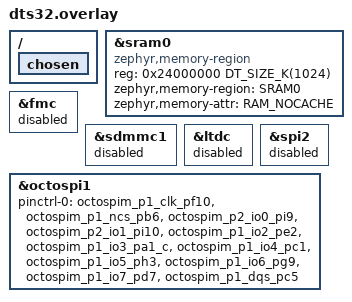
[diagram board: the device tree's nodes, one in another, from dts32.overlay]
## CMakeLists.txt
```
#
# Copyright (c) 2022 Nordic Semiconductor ASA
#
# SPDX-License-Identifier: LicenseRef-Nordic-5-Clause
#

cmake_minimum_required(VERSION 3.20.0)

find_package(Zephyr REQUIRED HINTS $ENV{ZEPHYR_BASE})
project(nrf_wifi_shell)

target_sources(app PRIVATE src/main.c)
```

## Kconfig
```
#
# Copyright (c) 2023 Nordic Semiconductor
#
# SPDX-License-Identifier: LicenseRef-Nordic-5-Clause
#

source "Kconfig.zephyr"

menu "Nordic Scan sample"

config APP_ENABLE_QSPI
	bool "select qspi driver"
	select USE_STM32_HAL_OSPI
	select USE_STM32_HAL_GPIO
	select USE_STM32_HAL_MDMA

endmenu
```

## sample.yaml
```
sample:
  description: Wi-Fi shell sample
    application
  name: Wi-Fi shell
tests:
  sample.nrf7002.shell:
    build_only: true
    integration_platforms:
      - nrf7002dk_nrf5340_cpuapp
    platform_allow: nrf7002dk_nrf5340_cpuapp
    tags: ci_build
  sample.nrf7001.shell:
    build_only: true
    integration_platforms:
      - nrf7002dk_nrf7001_nrf5340_cpuapp
    platform_allow: nrf7002dk_nrf7001_nrf5340_cpuapp
    tags: ci_build
  sample.nrf7002_eks.shell:
    build_only: true
    extra_args: SHIELD=nrf7002ek
    integration_platforms:
      - nrf5340dk_nrf5340_cpuapp
      - nrf52840dk_nrf52840
    platform_allow: nrf5340dk_nrf5340_cpuapp nrf52840dk_nrf52840
    tags: ci_build
  sample.nrf7000_eks.shell:
    build_only: true
    extra_args: SHIELD=nrf7002ek_nrf7000 CONFIG_WPA_SUPP=n
    integration_platforms:
      - nrf5340dk_nrf5340_cpuapp
      - nrf52840dk_nrf52840
    platform_allow: nrf5340dk_nrf5340_cpuapp nrf52840dk_nrf52840
    tags: ci_build
  sample.nrf7001_eks.shell:
    build_only: true
    extra_args: SHIELD=nrf7002ek_nrf7001
    integration_platforms:
      - nrf5340dk_nrf5340_cpuapp
      - nrf52840dk_nrf52840
    platform_allow: nrf5340dk_nrf5340_cpuapp nrf52840dk_nrf52840
    tags: ci_build
  sample.nrf7002_eks_cpunet.shell:
    build_only: true
    extra_args: SHIELD=nrf7002ek CONFIG_BOARD_ENABLE_CPUNET=y
    integration_platforms:
      - nrf5340dk_nrf5340_cpuapp
    platform_allow: nrf5340dk_nrf5340_cpuapp
    tags: ci_build
  sample.nrf7000_eks_cpunet.shell:
    build_only: true
    extra_args: SHIELD=nrf7002ek_nrf7000 CONFIG_BOARD_ENABLE_CPUNET=y CONFIG_WPA_SUPP=n
    integration_platforms:
      - nrf5340dk_nrf5340_cpuapp
    platform_allow: nrf5340dk_nrf5340_cpuapp
    tags: ci_build
  sample.nrf7001_eks_cpunet.shell:
    build_only: true
    extra_args: SHIELD=nrf7002ek_nrf7001 CONFIG_BOARD_ENABLE_CPUNET=y
    integration_platforms:
      - nrf5340dk_nrf5340_cpuapp
    platform_allow: nrf5340dk_nrf5340_cpuapp
    tags: ci_build
  sample.nrf7002.shell.zperf:
    build_only: true
    extra_args: OVERLAY_CONFIG=overlay-zperf.conf
    integration_platforms:
      - nrf7002dk_nrf5340_cpuapp
    platform_allow: nrf7002dk_nrf5340_cpuapp
    tags: ci_build
  sample.nrf7001.shell.zperf:
    build_only: true
    extra_args: OVERLAY_CONFIG=overlay-zperf.conf
    integration_platforms:
      - nrf7002dk_nrf7001_nrf5340_cpuapp
    platform_allow: nrf7002dk_nrf7001_nrf5340_cpuapp
    tags: ci_build
  sample.nrf7002.shell.wpa_cli:
    build_only: true
    extra_args: CONFIG_WPA_CLI=y
    integration_platforms:
      - nrf7002dk_nrf5340_cpuapp
    platform_allow: nrf7002dk_nrf5340_cpuapp
    tags: ci_build
  sample.nrf7001.shell.wpa_cli:
    build_only: true
    extra_args: CONFIG_WPA_CLI=y
    integration_platforms:
      - nrf7002dk_nrf7001_nrf5340_cpuapp
    platform_allow: nrf7002dk_nrf7001_nrf5340_cpuapp
    tags: ci_build
  sample.nrf7002.shell.scan_only_7002:
    build_only: true
    extra_args: OVERLAY_CONFIG=overlay-scan-only.conf
    integration_platforms:
      - nrf7002dk_nrf5340_cpuapp
    platform_allow: nrf7002dk_nrf5340_cpuapp
    tags: ci_build
  sample.nrf7002.shell.scan_only_9160:
    build_only: true
    extra_args: OVERLAY_CONFIG=overlay-scan-only.conf SHIELD=nrf7002ek
    integration_platforms:
      - nrf9160dk_nrf9160_ns
    platform_allow: nrf9160dk_nrf9160_ns
    tags: ci_build
  sample.nrf7000.shell.scan_only_9160:
    build_only: true
    extra_args: OVERLAY_CONFIG=overlay-scan-only.conf SHIELD=nrf7002ek_nrf7000 CONFIG_WPA_SUPP=n
    integration_platforms:
      - nrf9160dk_nrf9160_ns
    platform_allow: nrf9160dk_nrf9160_ns
    tags: ci_build
  sample.nrf7001.shell.scan_only_9160:
    build_only: true
    extra_args: OVERLAY_CONFIG=overlay-scan-only.conf SHIELD=nrf7002ek_nrf7001
    integration_platforms:
      - nrf9160dk_nrf9160_ns
    platform_allow: nrf9160dk_nrf9160_ns
    tags: ci_build
  sample.nrf7002.shell.otbr:
    build_only: true
    extra_args: OVERLAY_CONFIG=overlay-openthread.conf
    integration_platforms:
      - nrf7002dk_nrf5340_cpuapp
    platform_allow: nrf7002dk_nrf5340_cpuapp
    tags: ci_build
  sample.nrf7002.shell.posix_names:
    build_only: true
    extra_args: CONFIG_POSIX_API=n CONIFG_NET_SOCKETS_POSIX_NAMES=y
    integration_platforms:
      - nrf7002dk_nrf5340_cpuapp
    platform_allow: nrf7002dk_nrf5340_cpuapp
    tags: ci_build
  sample.nrf7002_ns.shell:
    build_only: true
    extra_args: OVERLAY_CONFIG=overlay-tfm.conf
    integration_platforms:
      - nrf7002dk_nrf5340_cpuapp_ns
    platform_allow: nrf7002dk_nrf5340_cpuapp_ns
  sample.nrf7002_eb.thingy53.shell:
    build_only: true
    extra_args: SHIELD=nrf7002eb CONFIG_BOARD_ENABLE_CPUNET=y
    integration_platforms:
      - thingy53_nrf5340_cpuapp
    platform_allow: thingy53_nrf5340_cpuapp
    tags: ci_build
  # Used by QA and also acts as a memory stress test
  sample.nrf7001.superset:
    build_only: true
    extra_args:
      OVERLAY_CONFIG=overlay-zperf.conf
      CONFIG_NRF700X_UTIL=y
      CONFIG_WPA_CLI=y
      CONFIG_NET_IPV4_FRAGMENT=y
      CONFIG_NET_IPV4_FRAGMENT_MAX_PKT=24
    integration_platforms:
      - nrf7002dk_nrf7001_nrf5340_cpuapp
    platform_allow: nrf7002dk_nrf7001_nrf5340_cpuapp
    tags: ci_build_superset
  # Used by QA and also acts as a memory stress test
  sample.nrf7001_ek.superset:
    build_only: true
    extra_args:
      SHIELD=nrf7002ek_nrf7001
      OVERLAY_CONFIG=overlay-zperf.conf
      CONFIG_NRF700X_UTIL=y
      CONFIG_WPA_CLI=y
      CONFIG_NET_IPV4_FRAGMENT=y
      CONFIG_NET_IPV4_FRAGMENT_MAX_PKT=24
    integration_platforms:
      - nrf5340dk_nrf5340_cpuapp
    platform_allow: nrf5340dk_nrf5340_cpuapp
    tags: ci_build_superset
  # Used by QA and also acts as a memory stress test
  sample.nrf7002.superset:
    build_only: true
    extra_args:
      OVERLAY_CONFIG=overlay-zperf.conf
      CONFIG_NRF700X_UTIL=y
      CONFIG_WPA_CLI=y
      CONFIG_NET_IPV4_FRAGMENT=y
      CONFIG_NET_IPV4_FRAGMENT_MAX_PKT=24
    integration_platforms:
      - nrf7002dk_nrf5340_cpuapp
    platform_allow: nrf7002dk_nrf5340_cpuapp
    tags: ci_build_superset
  # Used by QA and also acts as a memory stress test
  sample.nrf7002_ek.superset:
    build_only: true
    extra_args:
      SHIELD=nrf7002ek
      OVERLAY_CONFIG=overlay-zperf.conf
      CONFIG_NRF700X_UTIL=y
      CONFIG_WPA_CLI=y
      CONFIG_NET_IPV4_FRAGMENT=y
      CONFIG_NET_IPV4_FRAGMENT_MAX_PKT=24
    integration_platforms:
      - nrf5340dk_nrf5340_cpuapp
    platform_allow: nrf5340dk_nrf5340_cpuapp
    tags: ci_build_superset
  sample.nrf7002.superset.debug:
    build_only: true
    extra_args:
      OVERLAY_CONFIG=overlay-debug.conf;overlay-zperf.conf
      CONFIG_NRF700X_UTIL=y
      CONFIG_WPA_CLI=y
      CONFIG_NET_IPV4_FRAGMENT=y
      CONFIG_NET_IPV4_FRAGMENT_MAX_PKT=24
    integration_platforms:
      - nrf7002dk_nrf5340_cpuapp
    platform_allow: nrf7002dk_nrf5340_cpuapp
    tags: ci_build_superset
```

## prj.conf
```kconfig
#
# Copyright (c) 2022 Nordic Semiconductor ASA
#
# SPDX-License-Identifier: LicenseRef-Nordic-5-Clause
#
CONFIG_WIFI=y
CONFIG_WIFI_NRF700X=y

# WPA supplicant
CONFIG_WPA_SUPP=y
CONFIG_NET_L2_WIFI_SHELL=y

# System settings
CONFIG_NEWLIB_LIBC=y
CONFIG_NEWLIB_LIBC_NANO=n

# Networking
CONFIG_NETWORKING=y
CONFIG_NET_SOCKETS=y
CONFIG_NET_LOG=y
CONFIG_NET_IPV6=y
CONFIG_NET_IPV4=y
CONFIG_NET_UDP=y
CONFIG_NET_TCP=y
CONFIG_NET_DHCPV4=y
CONFIG_DNS_RESOLVER=y

CONFIG_NET_STATISTICS=y
CONFIG_NET_STATISTICS_WIFI=y
CONFIG_NET_STATISTICS_USER_API=y

CONFIG_NET_PKT_RX_COUNT=8
CONFIG_NET_PKT_TX_COUNT=8

# Below section is the primary contributor to SRAM and is currently
# tuned for performance, but this will be revisited in the future.
CONFIG_NET_BUF_RX_COUNT=16
CONFIG_NET_BUF_TX_COUNT=16
CONFIG_NET_BUF_DATA_SIZE=128
CONFIG_NRF700X_RX_NUM_BUFS=16
CONFIG_NRF700X_MAX_TX_AGGREGATION=4
# nRF700x is main consumer: (16 + 8) * 1600 = ~40KB + ~40KB control path (experimental)
CONFIG_HEAP_MEM_POOL_SIZE=80000
CONFIG_NET_TC_TX_COUNT=1

CONFIG_NET_IF_UNICAST_IPV6_ADDR_COUNT=4
CONFIG_NET_IF_MCAST_IPV6_ADDR_COUNT=5
CONFIG_NET_MAX_CONTEXTS=5
CONFIG_NET_CONTEXT_SYNC_RECV=y

CONFIG_INIT_STACKS=y

CONFIG_NET_L2_ETHERNET=y
CONFIG_NET_SHELL=y

# Memories
CONFIG_MAIN_STACK_SIZE=4096
CONFIG_SHELL_STACK_SIZE=4096
CONFIG_NET_TX_STACK_SIZE=4096
CONFIG_NET_RX_STACK_SIZE=4096

# Debugging
CONFIG_STACK_SENTINEL=y
CONFIG_DEBUG_COREDUMP=y
CONFIG_DEBUG_COREDUMP_BACKEND_LOGGING=y
CONFIG_DEBUG_COREDUMP_MEMORY_DUMP_MIN=y
CONFIG_SHELL_CMDS_RESIZE=n
#CONFIG_DEBUG=y
CONFIG_WPA_SUPP_LOG_LEVEL_INF=y

# Kernel options
CONFIG_ENTROPY_GENERATOR=y

# Logging
CONFIG_LOG=y
CONFIG_PRINTK=y
CONFIG_SHELL=y
CONFIG_SHELL_GETOPT=y
CONFIG_DEVICE_SHELL=y
CONFIG_POSIX_CLOCK=y
CONFIG_DATE_SHELL=y
CONFIG_NET_CONFIG_AUTO_INIT=n

CONFIG_WIFI_MGMT_EXT=y
CONFIG_WIFI_CREDENTIALS=y
CONFIG_WIFI_CREDENTIALS_BACKEND_SETTINGS=y
CONFIG_FLASH=y
CONFIG_FLASH_PAGE_LAYOUT=y
CONFIG_FLASH_MAP=y
CONFIG_NVS=y
CONFIG_SETTINGS=y
CONFIG_SETTINGS_NVS=y

# printing of scan results puts pressure on queues in new locking
# design in net_mgmt. So, use a higher timeout for a crowded
# environment.
CONFIG_NET_MGMT_EVENT_QUEUE_TIMEOUT=5000


CONFIG_NRF_WIFI_LOW_POWER=n
CONFIG_APP_ENABLE_QSPI=y
CONFIG_DCACHE=n
CONFIG_WPA_SUPP_CRYPTO_LEGACY_BUILTIN=y
CONFIG_ENTROPY_GENERATOR=y
CONFIG_ENTROPY_STM32_RNG=y
CONFIG_ENTROPY_DEVICE_RANDOM_GENERATOR=y
CONFIG_WIFI_MGMT_EXT=n
CONFIG_WIFI_CREDENTIALS=n
CONFIG_WIFI_CREDENTIALS_BACKEND_SETTINGS=n
CONFIG_FLASH=n
CONFIG_FLASH_PAGE_LAYOUT=n
CONFIG_FLASH_MAP=n
CONFIG_NVS=n
CONFIG_SETTINGS=n
CONFIG_SETTINGS_NVS=n

CONFIG_NET_ZPERF=y
CONFIG_POSIX_MAX_FDS=16
# Optimized networking settings for performance
CONFIG_NET_PKT_RX_COUNT=100
CONFIG_NET_PKT_TX_COUNT=100
CONFIG_NET_BUF_RX_COUNT=100
CONFIG_NET_BUF_TX_COUNT=100
CONFIG_HEAP_MEM_POOL_SIZE=300000
CONFIG_NET_BUF_DATA_SIZE=1600
CONFIG_NRF700X_QSPI_LOW_POWER=n
#CONFIG_SPEED_OPTIMIZATIONS=y

# Necessary for zperf_tcp_receiver.c
CONFIG_NET_CONFIG_SETTINGS=y
CONFIG_NET_CONFIG_INIT_TIMEOUT=0

CONFIG_NRF700X_MAX_TX_AGGREGATION=12
CONFIG_NRF700X_MAX_TX_TOKENS=12
CONFIG_SPEED_OPTIMIZATIONS=y

CONFIG_ZPERF_WORK_Q_THREAD_PRIORITY=5
# CONFIG_NRF700X_BH_WQ_PRIORITY=0
# CONFIG_NRF700X_MAX_TX_PENDING_QLEN=30

CONFIG_NET_ZPERF_MAX_PACKET_SIZE=1500

# add by liming
CONFIG_TEST_RANDOM_GENERATOR=y
CONFIG_ENTROPY_DEVICE_RANDOM_GENERATOR=y
CONFIG_HARDWARE_DEVICE_CS_GENERATOR=y
```

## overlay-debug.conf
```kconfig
CONFIG_SHELL=y
CONFIG_SHELL_STACK_SIZE=4096
CONFIG_NET_SHELL=y
CONFIG_SHELL_GETOPT=y
CONFIG_SHELL_CMDS_RESIZE=n
CONFIG_NRF700X_UTIL=y
CONFIG_NET_L2_WIFI_SHELL=y
CONFIG_NET_STATISTICS=y
CONFIG_NET_STATISTICS_WIFI=y
CONFIG_NET_STATISTICS_USER_API=y
CONFIG_SYS_HEAP_RUNTIME_STATS=y
CONFIG_LOG=y
CONFIG_PRINTK=y
CONFIG_LOG_MODE_IMMEDIATE=y
CONFIG_WPA_SUPP_LOG_LEVEL_DBG=y
```

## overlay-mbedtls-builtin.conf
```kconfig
CONFIG_WPA_SUPP_CRYPTO_LEGACY_BUILTIN=y
CONFIG_MBEDTLS_BUILTIN=y
CONFIG_ENTROPY_GENERATOR=y
# To fix Kconfig MD5 warning
CONFIG_NET_TCP_ISN_RFC6528=n
```

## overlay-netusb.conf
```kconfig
# USB Device settings
CONFIG_USB_DEVICE_STACK=y

# Select USB Configurations
CONFIG_USB_DEVICE_NETWORK_ECM=y

# Logging
CONFIG_USB_DRIVER_LOG_LEVEL_INF=y
CONFIG_USB_DEVICE_LOG_LEVEL_INF=y

# Uses more Selects
CONFIG_NET_SOCKETS_POLL_MAX=10

# DUT responses are > 1500, so, need to fragment
CONFIG_NET_IPV4_FRAGMENT=y
CONFIG_NET_IPV4_FRAGMENT_MAX_COUNT=10

# For netusb WFA_THREADS_NUM
CONFIG_MAX_PTHREAD_COUNT=5
# Every pthread_create needs a mutex, and WFA DUT needs an extra mutex/thread
# CONFIG_MAX_PTHREAD_COUNT * 2
CONFIG_MAX_PTHREAD_MUTEX_COUNT=10
# Same as above: CONFIG_MAX_PTHREAD_COUNT * 2
CONFIG_MAX_PTHREAD_COND_COUNT=10
```

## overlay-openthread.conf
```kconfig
# for wifi_shell to work
CONFIG_NET_DEFAULT_IF_ETHERNET=y
CONFIG_NET_CONFIG_AUTO_INIT=n
CONFIG_NET_CONFIG_SETTINGS=y
CONFIG_NET_CONFIG_INIT_TIMEOUT=0

CONFIG_OPENTHREAD_SHELL=y
CONFIG_SHELL_ARGC_MAX=26
CONFIG_SHELL_CMD_BUFF_SIZE=416

# Enable OpenThread features set
CONFIG_OPENTHREAD_NORDIC_LIBRARY_MASTER=y

CONFIG_NET_L2_OPENTHREAD=y
# Openthread supports only IPv6 and is the first interface
CONFIG_NET_CONFIG_MY_IPV4_ADDR=""
CONFIG_NET_CONFIG_PEER_IPV4_ADDR=""

CONFIG_ASSERT=y
CONFIG_ASSERT_NO_COND_INFO=y
CONFIG_FPU=y

CONFIG_GPIO_SHELL=y

# Use printk to log messages
CONFIG_LOG_MODE_MINIMAL=y

# Log only errors/hard faults
CONFIG_LOG_MAX_LEVEL=1
```

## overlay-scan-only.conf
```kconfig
# Scan only using offload API
CONFIG_WPA_SUPP=n
# In 9160 default is socket interface
CONFIG_NET_DEFAULT_IF_ETHERNET=y
CONFIG_MBEDTLS=n
CONFIG_NORDIC_SECURITY_BACKEND=n
# If MbedTLS is enabled, use the standard files
CONFIG_GENERATE_MBEDTLS_CFG_FILE=y

# Disable unused networking options
CONFIG_NET_SOCKETS=n
CONFIG_POSIX_API=n
CONFIG_NET_LOG=n
CONFIG_NET_IPV6=n
CONFIG_NET_TCP=n
CONFIG_DNS_RESOLVER=n

# Memories
CONFIG_NET_PKT_RX_COUNT=1
CONFIG_NET_PKT_TX_COUNT=1
# Needed to handle more scan results
CONFIG_HEAP_MEM_POOL_SIZE=25000
```

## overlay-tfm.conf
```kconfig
#
# Copyright (c) 2023 Nordic Semiconductor ASA
#
# SPDX-License-Identifier: LicenseRef-Nordic-5-Clause
#
CONFIG_NET_STATISTICS=n
CONFIG_NET_STATISTICS_WIFI=n
CONFIG_NET_STATISTICS_USER_API=n

CONFIG_NET_PKT_RX_COUNT=8
CONFIG_NET_PKT_TX_COUNT=4

# Below section is the primary contributor to SRAM and is currently
# tuned for performance, but this will be revisited in the future.
CONFIG_NET_BUF_RX_COUNT=8
CONFIG_NET_BUF_TX_COUNT=8
CONFIG_NET_BUF_DATA_SIZE=128
CONFIG_HEAP_MEM_POOL_SIZE=153600
CONFIG_NET_TC_TX_COUNT=1

CONFIG_NET_TX_STACK_SIZE=2048
CONFIG_NET_RX_STACK_SIZE=2048

# printing of scan results puts pressure on queues in new locking
# design in net_mgmt. So, use a higher timeout for a crowded
# environment.
CONFIG_NET_MGMT_EVENT_QUEUE_TIMEOUT=5000

CONFIG_MBEDTLS_PSA_CRYPTO_C=y
CONFIG_MBEDTLS_HEAP_SIZE=1024
```

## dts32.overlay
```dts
#include <st/h7/stm32h7b3lihxq-pinctrl.dtsi>

/delete-node/ &sram1;
/delete-node/ &sram2;
&sram0 {
	compatible = "zephyr,memory-region", "mmio-sram";
	reg = < 0x24000000 DT_SIZE_K(1024) >;
	zephyr,memory-region = "SRAM0";
	zephyr,memory-attr = "RAM_NOCACHE";
};

/{
	chosen {
		/delete-property/ zephyr,dtcm;
		/delete-property/ zephyr,itcm;
	};

};

&fmc {
	status = "disabled";
};

&sdmmc1 {
	status = "disabled";
};

&ltdc {
	status = "disabled";
};

&spi2 {
	status = "disabled";
};

&octospi1 {
	pinctrl-0 = <&octospim_p1_clk_pf10 &octospim_p1_ncs_pb6
		     &octospim_p2_io0_pi9 &octospim_p2_io1_pi10
		     &octospim_p1_io2_pe2 &octospim_p1_io3_pa1_c
		     &octospim_p1_io4_pc1 &octospim_p1_io5_ph3
		     &octospim_p1_io6_pg9 &octospim_p1_io7_pd7
		     &octospim_p1_dqs_pc5>;
	pinctrl-names = "default";

	status = "okay";	
};

// &pll {
// 	mul-n = <30>;

// };

// &rcc {
// 	clock-frequency = <DT_FREQ_M(240)>;
// };
```

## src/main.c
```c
/*
 * Copyright (c) 2022 Nordic Semiconductor ASA
 *
 * SPDX-License-Identifier: LicenseRef-Nordic-5-Clause
 */

/** @file
 * @brief WiFi shell sample main function
 */

#include <zephyr/sys/printk.h>
#include <zephyr/kernel.h>
#if defined(CLOCK_FEATURE_HFCLK_DIVIDE_PRESENT) || NRF_CLOCK_HAS_HFCLK192M
#include <nrfx_clock.h>
#endif
#include <zephyr/device.h>
#include <zephyr/net/net_config.h>

#ifdef CONFIG_SLIP
/* Fixed address as the static IP given from Kconfig will be
 * applied to Wi-Fi interface.
 */
#define CONFIG_NET_CONFIG_SLIP_IPV4_ADDR "192.0.2.1"
#define CONFIG_NET_CONFIG_SLIP_IPV4_MASK "255.255.255.0"
#endif /* CONFIG_SLIP */

#ifdef CONFIG_USB_DEVICE_STACK
#include <zephyr/usb/usb_device.h>

/* Fixed address as the static IP given from Kconfig will be
 * applied to Wi-Fi interface.
 */
#define CONFIG_NET_CONFIG_USB_IPV4_ADDR "192.0.2.1"
#define CONFIG_NET_CONFIG_USB_IPV4_MASK "255.255.255.0"

int init_usb(void)
{
	int ret;

	ret = usb_enable(NULL);
	if (ret != 0) {
		printk("Cannot enable USB (%d)", ret);
		return ret;
	}

	return 0;
}
#endif


int main(void)
{
#if defined(CONFIG_USB_DEVICE_STACK) || defined(CONFIG_SLIP)
	struct in_addr addr;
#endif

#if defined(CLOCK_FEATURE_HFCLK_DIVIDE_PRESENT) || NRF_CLOCK_HAS_HFCLK192M
	/* For now hardcode to 128MHz */
	nrfx_clock_divider_set(NRF_CLOCK_DOMAIN_HFCLK,
			       NRF_CLOCK_HFCLK_DIV_1);
#endif
	printk("Starting %s with CPU frequency: %d MHz\n", CONFIG_BOARD, SystemCoreClock/MHZ(1));

#ifdef CONFIG_USB_DEVICE_STACK
	init_usb();

	/* Redirect static IP address to netusb*/
	const struct device *usb_dev = device_get_binding("eth_netusb");
	struct net_if *iface = net_if_lookup_by_dev(usb_dev);

	if (!iface) {
		printk("Cannot find network interface: %s", "eth_netusb");
		return -1;
	}
	if (sizeof(CONFIG_NET_CONFIG_USB_IPV4_ADDR) > 1) {
		if (net_addr_pton(AF_INET, CONFIG_NET_CONFIG_USB_IPV4_ADDR, &addr)) {
			printk("Invalid address: %s", CONFIG_NET_CONFIG_USB_IPV4_ADDR);
			return -1;
		}
		net_if_ipv4_addr_add(iface, &addr, NET_ADDR_MANUAL, 0);
	}

	if (sizeof(CONFIG_NET_CONFIG_USB_IPV4_MASK) > 1) {
		/* If not empty */
		if (net_addr_pton(AF_INET, CONFIG_NET_CONFIG_USB_IPV4_MASK, &addr)) {
			printk("Invalid netmask: %s", CONFIG_NET_CONFIG_USB_IPV4_MASK);
		} else {
			net_if_ipv4_set_netmask(iface, &addr);
		}
	}
#endif

#ifdef CONFIG_SLIP
	const struct device *slip_dev = device_get_binding(CONFIG_SLIP_DRV_NAME);
	struct net_if *slip_iface = net_if_lookup_by_dev(slip_dev);

	if (!slip_iface) {
		printk("Cannot find network interface: %s", CONFIG_SLIP_DRV_NAME);
		return -1;
	}

	if (sizeof(CONFIG_NET_CONFIG_SLIP_IPV4_ADDR) > 1) {
		if (net_addr_pton(AF_INET, CONFIG_NET_CONFIG_SLIP_IPV4_ADDR, &addr)) {
			printk("Invalid address: %s", CONFIG_NET_CONFIG_SLIP_IPV4_ADDR);
			return -1;
		}
		net_if_ipv4_addr_add(slip_iface, &addr, NET_ADDR_MANUAL, 0);
	}

	if (sizeof(CONFIG_NET_CONFIG_SLIP_IPV4_MASK) > 1) {
		/* If not empty */
		if (net_addr_pton(AF_INET, CONFIG_NET_CONFIG_SLIP_IPV4_MASK, &addr)) {
			printk("Invalid netmask: %s", CONFIG_NET_CONFIG_SLIP_IPV4_MASK);
		} else {
			net_if_ipv4_set_netmask(slip_iface, &addr);
		}
	}
#endif /* CONFIG_SLIP */

#ifdef CONFIG_NET_CONFIG_SETTINGS
	/* Without this, DHCPv4 starts on first interface and if that is not Wi-Fi or
	 * only supports IPv6, then its an issue. (E.g., OpenThread)
	 *
	 * So, we start DHCPv4 on Wi-Fi interface always, independent of the ordering.
	 */
	/* TODO: Replace device name with DTS settings later */
	const struct device *dev = device_get_binding("wlan0");
	struct net_if *wifi_iface = net_if_lookup_by_dev(dev);

	/* As both are Ethernet, we need to set specific interface*/
	net_if_set_default(wifi_iface);

	net_config_init_app(dev, "Initializing network");
#endif

	return 0;
}
```
